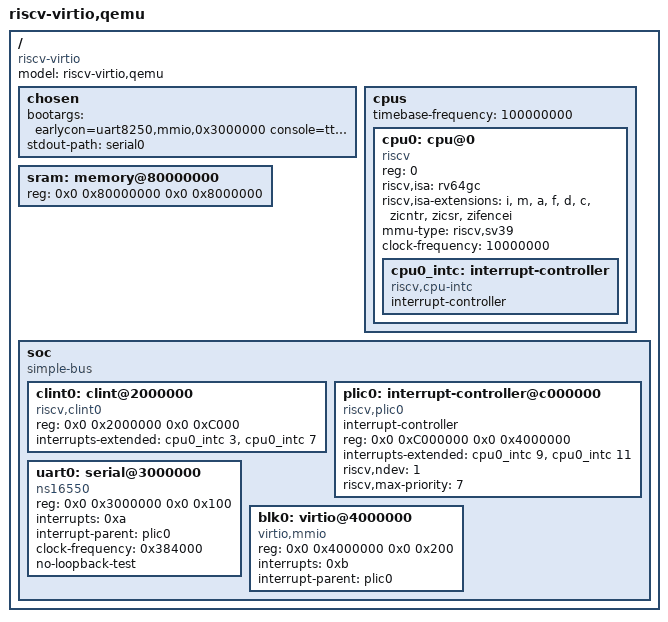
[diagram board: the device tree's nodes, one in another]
/dts-v1/;
/ {
    #address-cells = <2>;
    #size-cells = <2>;
    compatible = "riscv-virtio";
    model = "riscv-virtio,qemu";

    chosen {
        bootargs = "earlycon=uart8250,mmio,0x3000000 console=ttyS0";
        stdout-path = "serial0";
    };

    cpus {
        #address-cells = <1>;
        #size-cells = <0>;
        timebase-frequency = <100000000>;

        cpu0: cpu@0 {
            device_type = "cpu";
            reg = <0>;
            compatible = "riscv";
            riscv,isa = "rv64gc";
            riscv,isa-extensions = "i", "m", "a", "f", "d", "c", "zicntr", "zicsr", "zifencei";
            mmu-type = "riscv,sv39";
            clock-frequency = <10000000>;
            cpu0_intc: interrupt-controller {
                #address-cells = <1>;
                #interrupt-cells = <1>;
                compatible = "riscv,cpu-intc";
                interrupt-controller;
            };
        };
    };

    sram: memory@80000000 {
        device_type = "memory";
        reg = <0x0 0x80000000 0x0 0x8000000>;
    };

    soc {
        #address-cells = <2>;
        #size-cells = <2>;
        compatible = "simple-bus";
        ranges;

        clint0: clint@2000000 {
            compatible = "riscv,clint0";
            reg = <0x0 0x2000000 0x0 0xC000>;
            interrupts-extended =  <&cpu0_intc 3 &cpu0_intc 7>;
        };

        plic0: interrupt-controller@c000000 {
            #address-cells = <2>;
            #interrupt-cells = <1>;
            interrupt-controller;
            compatible = "riscv,plic0";
            reg = <0x0 0xC000000 0x0 0x4000000>;
            interrupts-extended = <&cpu0_intc 9>, <&cpu0_intc 11>;
            riscv,ndev = <1>;
            riscv,max-priority = <7>;
        };

        uart0: serial@3000000 {
            compatible = "ns16550";
            reg = <0x0 0x3000000 0x0 0x100>;
            interrupts = <0xa>;
            interrupt-parent = <&plic0>;
            clock-frequency = <0x384000>;
            no-loopback-test;
        };

        blk0: virtio@4000000 {
            compatible = "virtio,mmio";
            reg = <0x0 0x4000000 0x0 0x200>;
            interrupts = <0xb>;
            interrupt-parent = <&plic0>;
        };
    };
};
